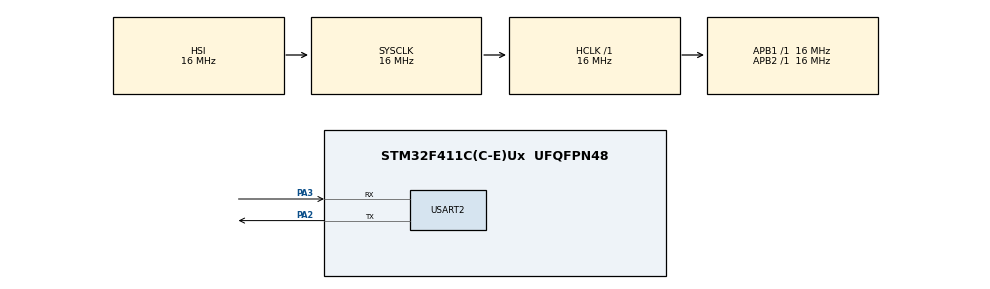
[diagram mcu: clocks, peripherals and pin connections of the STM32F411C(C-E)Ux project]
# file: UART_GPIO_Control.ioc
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Mcu.Family=STM32F4
Mcu.Name=STM32F411C(C-E)Ux
Mcu.Package=UFQFPN48
NVIC.PriorityGroup=NVIC_PRIORITYGROUP_4
PA13.Mode=Serial_Wire
PA13.Signal=SYS_JTMS-SWDIO
PA14.Mode=Serial_Wire
PA14.Signal=SYS_JTCK-SWCLK
PA2.Mode=Asynchronous
PA2.Signal=USART2_TX
PA3.Mode=Asynchronous
PA3.Signal=USART2_RX
ProjectManager.HeapSize=0x200
ProjectManager.StackSize=0x400
ProjectManager.TargetToolchain=STM32CubeIDE
RCC.AHBFreq_Value=16000000
RCC.APB1Freq_Value=16000000
RCC.APB2Freq_Value=16000000
RCC.CortexFreq_Value=16000000
RCC.HSE_VALUE=25000000
RCC.HSI_VALUE=16000000
RCC.LSE_VALUE=32768
RCC.SYSCLKFreq_VALUE=16000000
RCC.VCOOutputFreq_Value=192000000
USART2.VirtualMode=VM_ASYNC
board=custom

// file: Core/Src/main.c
/* USER CODE BEGIN Header */
/**
  ******************************************************************************
  * @file           : main.c
  * @brief          : Main program body
  ******************************************************************************
  * @attention
  *
  * Copyright (c) 2026 STMicroelectronics.
  * All rights reserved.
  *
  * This software is licensed under terms that can be found in the LICENSE file
  * in the root directory of this software component.
  * If no LICENSE file comes with this software, it is provided AS-IS.
  *
  ******************************************************************************
  */
/* USER CODE END Header */
#include "main.h"

/* USER CODE BEGIN Includes */
#include <stdio.h>
#include <string.h>
#include <stdint.h>
/* USER CODE END Includes */

UART_HandleTypeDef huart2;

/* USER CODE BEGIN PV */

#define UART_BUFFER_SIZE 64

uint8_t rx_byte;
char uart_buffer[UART_BUFFER_SIZE];
uint8_t uart_index = 0;
uint8_t uart_overflow = 0;

/* USER CODE END PV */

void SystemClock_Config(void);
static void MX_GPIO_Init(void);
static void MX_USART2_UART_Init(void);

/* USER CODE BEGIN 0 */

// Send text through USART2
static void UART_Send(const char *message)
{
    HAL_UART_Transmit(&huart2,
                      (uint8_t *)message,
                      (uint16_t)strlen(message),
                      100);
}

// Execute GPIO commands received through UART
static void Process_Command(const char *command)
{
    char port_name[6] = {0};
    char state[8] = {0};
    char extra;
    int pin_number;

    GPIO_TypeDef *port = NULL;
    GPIO_PinState pin_state;

    // Expected format: GPIOA 5 HIGH
    if (sscanf(command, "%5s %d %7s %c",
               port_name, &pin_number,
               state, &extra) != 3)
    {
        UART_Send("ERROR: Invalid command\r\n");
        return;
    }

    // Identify the GPIO port
    if (strcmp(port_name, "GPIOA") == 0)
    {
        port = GPIOA;
    }
    else if (strcmp(port_name, "GPIOB") == 0)
    {
        port = GPIOB;
    }
    else if (strcmp(port_name, "GPIOC") == 0)
    {
        port = GPIOC;
    }
    else
    {
        UART_Send("ERROR: Invalid port\r\n");
        return;
    }

    // Validate pin number
    if (pin_number < 0 || pin_number > 15)
    {
        UART_Send("ERROR: Invalid pin\r\n");
        return;
    }

    // Protect UART, SWD, USB and special pins
    if ((port == GPIOA &&
         (pin_number == 2 || pin_number == 3 ||
          pin_number == 11 || pin_number == 12 ||
          pin_number == 13 || pin_number == 14)) ||
        (port == GPIOB &&
         (pin_number == 2 || pin_number == 11)) ||
        (port == GPIOC && pin_number != 13))
    {
        UART_Send("ERROR: Reserved pin\r\n");
        return;
    }

    // Determine output state
    if (strcmp(state, "HIGH") == 0)
    {
        pin_state = GPIO_PIN_SET;
    }
    else if (strcmp(state, "LOW") == 0)
    {
        pin_state = GPIO_PIN_RESET;
    }
    else
    {
        UART_Send("ERROR: Use HIGH or LOW\r\n");
        return;
    }

    // Enable the GPIO peripheral clock
    if (port == GPIOA)
        __HAL_RCC_GPIOA_CLK_ENABLE();
    else if (port == GPIOB)
        __HAL_RCC_GPIOB_CLK_ENABLE();
    else if (port == GPIOC)
        __HAL_RCC_GPIOC_CLK_ENABLE();

    uint16_t pin = (uint16_t)(1U << pin_number);

    // Preload the requested output level
    HAL_GPIO_WritePin(port, pin, pin_state);

    // Configure pin as output
    GPIO_InitTypeDef GPIO_InitStruct = {0};

    GPIO_InitStruct.Pin = pin;
    GPIO_InitStruct.Mode = GPIO_MODE_OUTPUT_PP;
    GPIO_InitStruct.Pull = GPIO_NOPULL;
    GPIO_InitStruct.Speed = GPIO_SPEED_FREQ_LOW;

    HAL_GPIO_Init(port, &GPIO_InitStruct);

    UART_Send("OK: GPIO updated\r\n");
}

/* USER CODE END 0 */

int main(void)
{

  /* MCU Configuration--------------------------------------------------------*/

  /* Reset of all peripherals, Initializes the Flash interface and the Systick. */
  HAL_Init();

  /* Configure the system clock */
  SystemClock_Config();

  /* Initialize all configured peripherals */
  MX_GPIO_Init();
  MX_USART2_UART_Init();
  /* USER CODE BEGIN 2 */

  UART_Send("\r\nUART GPIO Control Ready\r\n");
  UART_Send("Example: GPIOA 5 HIGH\r\n");

  /* USER CODE END 2 */

  /* Infinite loop */
  while (1)
  {

    /* USER CODE BEGIN 3 */

	  if (HAL_UART_Receive(&huart2, &rx_byte, 1, 100)
	      == HAL_OK)
	  {
	      // End of command
	      if (rx_byte == '\r' || rx_byte == '\n')
	      {
	          if (uart_overflow)
	          {
	              UART_Send("ERROR: Command too long\r\n");
	          }
	          else if (uart_index > 0)
	          {
	              uart_buffer[uart_index] = '\0';

	              Process_Command(uart_buffer);
	          }

	          uart_index = 0;
	          uart_overflow = 0;
	      }
	      else if (!uart_overflow)
	      {
	          // Store received character
	          if (uart_index < UART_BUFFER_SIZE - 1)
	          {
	              uart_buffer[uart_index++] = (char)rx_byte;
	          }
	          else
	          {
	              uart_overflow = 1;
	          }
	      }
	  }
  }
  /* USER CODE END 3 */
}

void SystemClock_Config(void)
{
  RCC_OscInitTypeDef RCC_OscInitStruct = {0};
  RCC_ClkInitTypeDef RCC_ClkInitStruct = {0};

  /** Configure the main internal regulator output voltage
  */
  __HAL_RCC_PWR_CLK_ENABLE();
  __HAL_PWR_VOLTAGESCALING_CONFIG(PWR_REGULATOR_VOLTAGE_SCALE1);

  /** Initializes the RCC Oscillators according to the specified parameters
  * in the RCC_OscInitTypeDef structure.
  */
  RCC_OscInitStruct.OscillatorType = RCC_OSCILLATORTYPE_HSI;
  RCC_OscInitStruct.HSIState = RCC_HSI_ON;
  RCC_OscInitStruct.HSICalibrationValue = RCC_HSICALIBRATION_DEFAULT;
  RCC_OscInitStruct.PLL.PLLState = RCC_PLL_NONE;
  if (HAL_RCC_OscConfig(&RCC_OscInitStruct) != HAL_OK)
  {
    Error_Handler();
  }

  /** Initializes the CPU, AHB and APB buses clocks
  */
  RCC_ClkInitStruct.ClockType = RCC_CLOCKTYPE_HCLK|RCC_CLOCKTYPE_SYSCLK
                              |RCC_CLOCKTYPE_PCLK1|RCC_CLOCKTYPE_PCLK2;
  RCC_ClkInitStruct.SYSCLKSource = RCC_SYSCLKSOURCE_HSI;
  RCC_ClkInitStruct.AHBCLKDivider = RCC_SYSCLK_DIV1;
  RCC_ClkInitStruct.APB1CLKDivider = RCC_HCLK_DIV1;
  RCC_ClkInitStruct.APB2CLKDivider = RCC_HCLK_DIV1;

  if (HAL_RCC_ClockConfig(&RCC_ClkInitStruct, FLASH_LATENCY_0) != HAL_OK)
  {
    Error_Handler();
  }
}

static void MX_USART2_UART_Init(void)
{

  huart2.Instance = USART2;
  huart2.Init.BaudRate = 115200;
  huart2.Init.WordLength = UART_WORDLENGTH_8B;
  huart2.Init.StopBits = UART_STOPBITS_1;
  huart2.Init.Parity = UART_PARITY_NONE;
  huart2.Init.Mode = UART_MODE_TX_RX;
  huart2.Init.HwFlowCtl = UART_HWCONTROL_NONE;
  huart2.Init.OverSampling = UART_OVERSAMPLING_16;
  if (HAL_UART_Init(&huart2) != HAL_OK)
  {
    Error_Handler();
  }

}

static void MX_GPIO_Init(void)
{

  /* GPIO Ports Clock Enable */
  __HAL_RCC_GPIOA_CLK_ENABLE();

}

void Error_Handler(void)
{
  __disable_irq();
  while (1)
  {
  }
}
